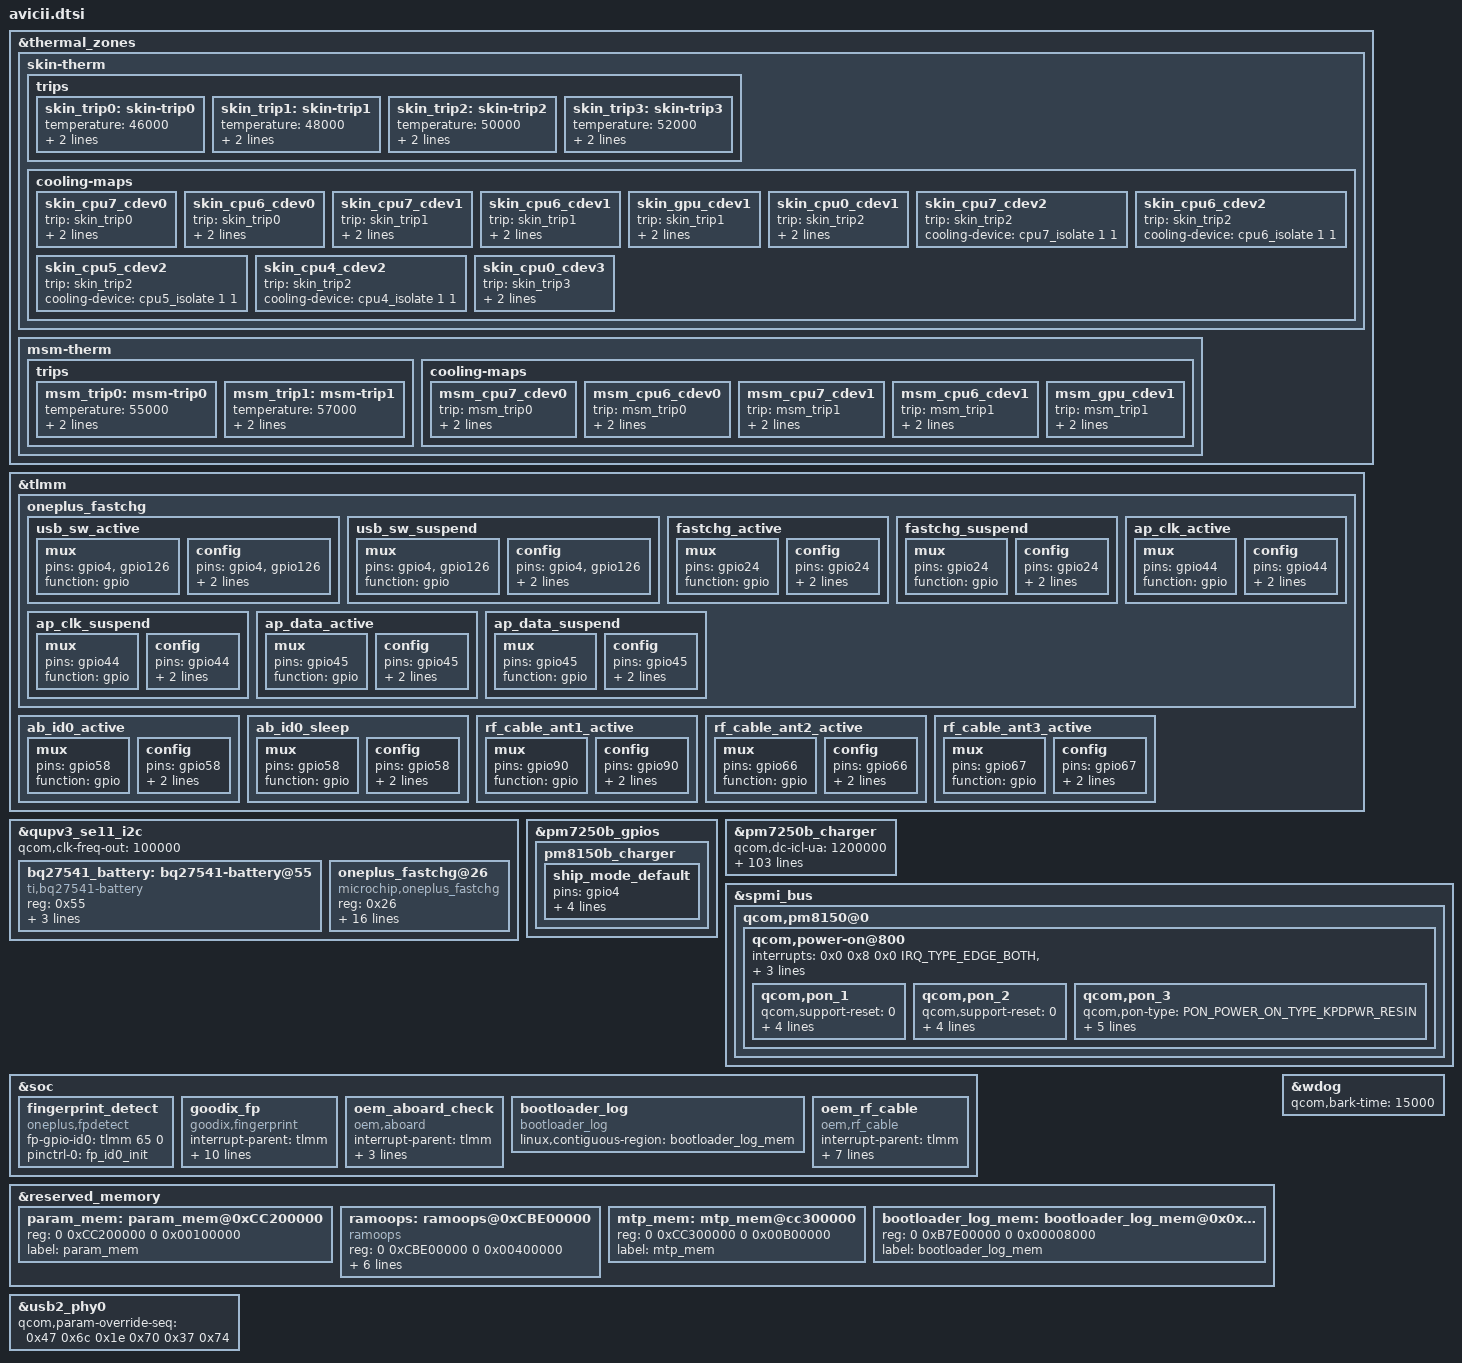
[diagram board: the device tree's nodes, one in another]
/*this is for different project dtsi*/
&thermal_zones {
	skin-therm {
		trips {
			skin_trip0: skin-trip0 {
				temperature = <46000>;
				hysteresis = <2000>;
				type = "passive";
			};

			skin_trip1: skin-trip1 {
				temperature = <48000>;
				hysteresis = <2000>;
				type = "passive";
			};

			skin_trip2: skin-trip2 {
				temperature = <50000>;
				hysteresis = <2000>;
				type = "passive";
			};

			skin_trip3: skin-trip3 {
				temperature = <52000>;
				hysteresis = <2000>;
				type = "passive";
			};
		};

		cooling-maps {
			skin_cpu7_cdev0 {
				trip = <&skin_trip0>;
					/* throttle from fmax to 1766400KHz */
				cooling-device =
					<&CPU7 (THERMAL_MAX_LIMIT-3)
						(THERMAL_MAX_LIMIT-3)>;
			};

			skin_cpu6_cdev0 {
				trip = <&skin_trip0>;
					/* throttle from fmax to 1728000KHz */
				cooling-device =
					<&CPU6 (THERMAL_MAX_LIMIT-4)
						(THERMAL_MAX_LIMIT-4)>;
			};

			skin_cpu7_cdev1 {
				trip = <&skin_trip1>;
					/* throttle from fmax to 1401600KHz */
				cooling-device = <&CPU7 (THERMAL_MAX_LIMIT-2)
						(THERMAL_MAX_LIMIT-2)>;
			};

			skin_cpu6_cdev1 {
				trip = <&skin_trip1>;
					/* throttle from fmax to 1478400KHz */
				cooling-device =
					<&CPU6 (THERMAL_MAX_LIMIT-3)
						(THERMAL_MAX_LIMIT-3)>;
			};

			skin_gpu_cdev1 {
				trip = <&skin_trip1>;
				cooling-device = <&msm_gpu (THERMAL_MAX_LIMIT-2)
						(THERMAL_MAX_LIMIT-2)>;
			};

			skin_cpu0_cdev1 {
				trip = <&skin_trip2>;
					/* throttle from fmax to 864000KHz */
				cooling-device =
					<&CPU0 (THERMAL_MAX_LIMIT-3)
						(THERMAL_MAX_LIMIT-3)>;
			};

			skin_cpu7_cdev2 {
				trip = <&skin_trip2>;
					/* throttle to close cpu7 */
				cooling-device = <&cpu7_isolate 1 1>;
			};

			skin_cpu6_cdev2 {
				trip = <&skin_trip2>;
					/* throttle to close cpu6 */
				cooling-device = <&cpu6_isolate 1 1>;
			};

			skin_cpu5_cdev2 {
				trip = <&skin_trip2>;
					/* throttle to close cpu5 */
				cooling-device = <&cpu5_isolate 1 1>;
			};

			skin_cpu4_cdev2 {
				trip = <&skin_trip2>;
					/* throttle to close cpu4 */
				cooling-device = <&cpu4_isolate 1 1>;
			};

			skin_cpu0_cdev3 {
				trip = <&skin_trip3>;
					/* throttle from fmax to 614400KHz */
				cooling-device =
					<&CPU0 (THERMAL_MAX_LIMIT-2)
						(THERMAL_MAX_LIMIT-2)>;
			};
		};
	};

	msm-therm {
		trips {
			msm_trip0: msm-trip0 {
				temperature = <55000>;
				hysteresis = <2000>;
				type = "passive";
			};

			msm_trip1: msm-trip1 {
				temperature = <57000>;
				hysteresis = <2000>;
				type = "passive";
			};
		};

		cooling-maps {
			msm_cpu7_cdev0 {
				trip = <&msm_trip0>;
					/* throttle from fmax to 2304000KHz */
				cooling-device =
					<&CPU7 (THERMAL_MAX_LIMIT-6)
						(THERMAL_MAX_LIMIT-6)>;
			};

			msm_cpu6_cdev0 {
				trip = <&msm_trip0>;
					/* throttle from fmax to 1900800KHz */
				cooling-device =
					<&CPU6 (THERMAL_MAX_LIMIT-5)
						(THERMAL_MAX_LIMIT-5)>;
			};

			msm_cpu7_cdev1 {
				trip = <&msm_trip1>;
					/* throttle from fmax to 1996800KHz */
				cooling-device = <&CPU0 (THERMAL_MAX_LIMIT-4)
						(THERMAL_MAX_LIMIT-4)>;
			};

			msm_cpu6_cdev1 {
				trip = <&msm_trip1>;
					/* throttle from fmax to 1728000KHz */
				cooling-device = <&CPU0 (THERMAL_MAX_LIMIT-4)
						(THERMAL_MAX_LIMIT-4)>;
			};

			msm_gpu_cdev1 {
				trip = <&msm_trip1>;
				cooling-device = <&msm_gpu (THERMAL_MAX_LIMIT-1)
						(THERMAL_MAX_LIMIT-1)>;
			};
		};
	};
};

&tlmm {
	oneplus_fastchg {
		usb_sw_active: usb_sw_active {
			mux {
				pins = "gpio4", "gpio126";
				function = "gpio";
			};

			config {
				pins = "gpio4", "gpio126";
				drive-strength = <16>;
				bias-pull-down;
			};
		};

		usb_sw_suspend: usb_sw_suspend {
			mux {
				pins = "gpio4", "gpio126";
				function = "gpio";
			};

			config {
				pins = "gpio4", "gpio126";
				drive-strength = <2>;
				bias-disable;
			};
		};

		fastchg_active: fastchg_active {
			mux {
				pins = "gpio24";
				function = "gpio";
			};

			config {
				pins = "gpio24";
				drive-strength = <16>;
				bias-pull-up;
			};
		};

		fastchg_suspend: fastchg_suspend {
			mux {
				pins = "gpio24";
				function = "gpio";
			};

			config {
				pins = "gpio24";
				drive-strength = <2>;
				bias-disable;
			};
		};

		ap_clk_active: ap_clk_active {
			mux {
				pins = "gpio44";
				function = "gpio";
			};

			config {
				pins = "gpio44";
				drive-strength = <16>;
				bias-pull-up;
			};
		};

		ap_clk_suspend: ap_clk_suspend {
			mux {
				pins = "gpio44";
				function = "gpio";
			};

			config {
				pins = "gpio44";
				drive-strength = <2>;
				bias-disable;
			};
		};

		ap_data_active: ap_data_active {
			mux {
				pins = "gpio45";
				function = "gpio";
			};

			config {
				pins = "gpio45";
				drive-strength = <16>;
				bias-pull-up;
			};
		};

		ap_data_suspend: ap_data_suspend {
			mux {
				pins = "gpio45";
				function = "gpio";
			};

			config {
				pins = "gpio45";
				drive-strength = <2>;
				bias-disable;
			};
		};
	};

	ab_id0_active: ab_id0_active {
		mux {
			pins = "gpio58";
			function = "gpio";
		};
		config {
			pins = "gpio58";
			drive-strength = <2>;
			bias-pull-up;
		};
	};
	ab_id0_sleep: ab_id0_sleep {
		mux {
			pins = "gpio58";
			function = "gpio";
		};
		config {
			pins = "gpio58";
			drive-strength = <2>;
			bias-disable;
		};
	};
        rf_cable_ant1_active: rf_cable_ant1_active {
            mux {
                pins = "gpio90";
                function = "gpio";
            };
            config {
                pins = "gpio90";
                drive-strength = <2>;
                bias-pull-up;
            };
        };
        rf_cable_ant2_active: rf_cable_ant2_active {
            mux {
                pins = "gpio66";
                function = "gpio";
            };
            config {
                pins = "gpio66";
                drive-strength = <2>;
                bias-pull-up;
            };
        };
        rf_cable_ant3_active: rf_cable_ant3_active {
            mux {
                pins = "gpio67";
                function = "gpio";
            };
            config {
                pins = "gpio67";
                drive-strength = <2>;
                bias-pull-up;
            };
        };
};
/* @bsp, 2019/07/08 Battery & Charging porting END */

&qupv3_se11_i2c {
	status = "ok";
	qcom,clk-freq-out = <100000>;
	bq27541_battery:bq27541-battery@55 {
		status = "ok";
		compatible = "ti,bq27541-battery";
		reg = <0x55>;
		qcom,modify-soc-smooth;
		qcom,battery-full-param;//only for wite battery full param in guage dirver probe on 7250 platform 
		op,bat-4p45v;
	};

	oneplus_fastchg@26{
		status = "ok";
		compatible = "microchip,oneplus_fastchg";
		reg = <0x26>;
		microchip,mcu-en-gpio = <&tlmm 24 0x00>;
		microchip,usb-sw-1-gpio = <&tlmm 4 0x00>;
		microchip,usb-sw-2-gpio = <&tlmm 126 0x00>;
		microchip,ap-clk = <&tlmm 44 0x00>;
		microchip,ap-data = <&tlmm 45 0x00>;

		pinctrl-names = "mux_fastchg_active",
		"mux_fastchg_suspend",
		"mcu_data_active",
		"mcu_data_suspend";
		pinctrl-0 = <&fastchg_active
		&usb_sw_active
		&ap_clk_active>;
		pinctrl-1 = <&usb_sw_suspend
		&fastchg_suspend
		&ap_clk_suspend>;
		pinctrl-2 =<&ap_data_active>;
		pinctrl-3 =<&ap_data_suspend>;
		op,fw-erase-count = <384>;
		op,fw-addr-low = <0x88>;
		op,fw-addr-high = <0>;
		op,4300mAh_4p45_support;
		op,mcl_verion;
	};
};

&pm7250b_gpios {
	pm8150b_charger {
		ship_mode_default: ship_mode_default {
			pins = "gpio4";
			function = "normal";
			power-source = <0>;
			bias-disable;
			input-disable;
		};
	};
};


&pm7250b_charger {
	qcom,dc-icl-ua = <1200000>;
	qcom,fcc-max-ua = <2000000>;
	qcom,usb-icl-ua = <1800000>;
	qcom,fv-max-uv = <4365000>;
	/* ibatmax setting for different temp regions */
	ibatmax-little-cold-ma = <350>;
	ibatmax-cool-ma = <2000>;
	ibatmax-little-cool-ma = <2000>;
	ibatmax-pre-normal-ma = <2000>;
	ibatmax-normal-ma = <2000>;
	ibatmax-warm-ma = <1150>;
	ibatmax-little-cool-thr-ma = <1900>;
	ibatmax-cool-thr-ma = <1150>;
	/* vbatmax setting for different temp regions */
	vbatmax-little-cold-mv = <3975>;
	vbatmax-cool-mv = <4435>;
	vbatmax-little-cool-mv = <4435>;
	vbatmax-pre-normal-mv = <4435>;
	vbatmax-normal-mv = <4435>;
	vbatmax-warm-mv = <4130>;
	little-cool-vbat-thr-mv = <4180>;
	cool-vbat-thr-mv = <4180>;
	/* vbatdet setting for different temp regions */
	vbatdet-little-cold-mv = <3675>;
	vbatdet-cool-mv = <4235>;
	vbatdet-little-cool-mv = <4335>;
	vbatdet-pre-normal-mv = <4335>;
	vbatdet-normal-mv = <4335>;
	vbatdet-warm-mv = <4030>;
	/* temp region settings */
	cold-bat-decidegc = <20>;
	little-cold-bat-decidegc = <0>;
	cool-bat-decidegc = <50>;
	little-cool-bat-decidegc = <120>;
	pre-normal-bat-decidegc = <160>;
	warm-bat-decidegc = <450>;
	hot-bat-decidegc = <500>;
	qcom,otg-cl-ua = <1500000>;
	op,sw-iterm-ma = <310>;
	op,sw-check-full-enable;
	/*ffc temp region*/
	ffc-pre-normal-decidegc = <120>;
	ffc-normal-decidegc = <350>;
	ffc-warm-decidegc = <400>;
	ffc-normal-fcc-ma = <1050>;
	ffc-warm-fcc-ma = <1100>;
	ffc-normal-cutoff-ma = <950>;
	ffc-warm-cutoff-ma = <1000>;
	ffc-full-vbat-mv = <4480>;

	/* skin thermal temp adjust the dash current */
	op,skin-thermal-high-threshold-disp-off = <42>;
	op,skin-thermal-pre-high-threshold-disp-off = <38>;
	op,skin-thermal-medium-threshold-disp-off = <39>;
	op,skin-thermal-normal-threshold-disp-off = <37>;

	op,skin-thermal-high-threshold-disp-on = <40>;
	op,skin-thermal-pre-high-threshold-disp-on = <39>;
	op,skin-thermal-little-high-threshold-disp-on = <38>;
	op,skin-thermal-pre-little-high-threshold-disp-on = <37>;
	op,skin-thermal-medium-threshold-disp-on = <36>;
	op,skin-thermal-normal-threshold-disp-on = <35>;
	op,enable-dash-current-dynamic-adjust;

	/* skin thermal temp adjust the pd current */
	op,pd-skin-thermal-high-threshold = <40>;
	op,pd-skin-thermal-normal-threshold = <38>;
	op,pd-skin-thermal-medium-threshold = <39>;
	op,pd-skin-thermal-pre-high-threshold = <39>;
	op,enable-pd-current-dynamic-adjust;

	/delete-property/ qcom,sw-jeita-enable;

	/*otg low battery current limit*/
	op,otg-icl-ctrl-enable;
	otg-low-battery-thr = <15>;
	otg-low-bat-icl-thr = <1000000>;
	otg-normal-bat-icl-thr = <1500000>;

	/* for usb connecter temperature check */
	op,normal-check-interval-period = <300>;
	op,fast-check-interval-period = <50>;
	op,fast-check-threshold-temp = <33>;
	op,high-temp-short-check-timeout = <1500>;
	op,first-protect-connecter-temp = <60>;
	op,second-protect-connecter-temp = <45>;
	op,second-protect-interval-temp = <14>;
	op,third-protect-rise-rate = <3>;
	op,third-protect-loop-temp = <40>;
	op,third-protect-interval-temp = <8>;
	op,third-protect-base-temp = <20>;

	/* for charge current&voltage curve optimize */
	op,fv-offset-voltage-mv = <50>;

	/* for 4p45v not charge full issue add sw full count numb */
	op,full-count-sw-numb = <2>;

	/* other settings */
	/*disable lpd*/
	qcom,lpd-disable;
	qcom,cutoff-voltage-with-charger = <3250>;
	qcom,msm-bus,name = "dash_clk_vote";
	qcom,msm-bus,num-cases = <2>;
	qcom,msm-bus,num-paths = <1>;
	qcom,msm-bus,vectors-KBps = <1 731 0 300000000>,
					<1 731 0 0>;

	/*usb connector hw auto detection*/
	op,usb-check = <&tlmm 68 0x00>;

	/* for external ship mode suppot */
	op,stm-ctrl-gpio = <&pm7250b_gpios 4 0x00>;
	pinctrl-names = "op_ship_mode_default",
			"op_usb_temp_adc_default",
			"op_usb_temp_adc_sec";

	pinctrl-0 = <&ship_mode_default>;
	pinctrl-1 = <&usb_tem1_adc_gpio_default>;
	pinctrl-2 = <&usb_tem2_adc_gpio_default>;

	io-channels = <&pm7250b_vadc ADC_USB_IN_V_16>,
		      <&pm7250b_vadc ADC_USB_IN_I>,
		      <&pm7250b_vadc ADC_CHG_TEMP>,
		      <&pm7250b_vadc ADC_DIE_TEMP>,
		      <&pm7250b_vadc ADC_AMUX_THM3_PU2>,
		      <&pm7250b_vadc ADC_SBUx>,
		      <&pm7250b_vadc ADC_VPH_PWR>,
		      <&pm7250b_vadc ADC_AMUX_THM1_PU2>,
		      <&pm8150l_vadc ADC_GPIO3_PU2>,
		      <&pm8150_vadc ADC_GPIO1_PU1>,
		      <&pm8150l_vadc ADC_GPIO2_PU1>;

	io-channel-names = "usb_in_voltage",
			   "usb_in_current",
			   "chg_temp",
			   "die_temp",
			   "conn_temp",
			   "sbux_res",
			   "vph_voltage",
			   "skin_temp",
			   "skin_therm",
			   "usb_tem1_adc",
			   "usb_tem2_adc";

	/* VBUS control config */
	op,vbus-ctrl-gpio = <&pm7250b_gpios 7 GPIO_ACTIVE_LOW>;
};


&spmi_bus {
	qcom,pm8150@0 {
		qcom,power-on@800 {
			interrupts = <0x0 0x8 0x0 IRQ_TYPE_EDGE_BOTH>,
			             <0x0 0x8 0x1 IRQ_TYPE_EDGE_BOTH>,
			             <0x0 0x8 0x5 IRQ_TYPE_EDGE_BOTH>;
			interrupt-names = "kpdpwr", "resin", "kpdpwr-resin-bark";
			qcom,s3-src = "kpdpwr-and-resin";

			qcom,pon_1 {
				qcom,support-reset = <0>;
				qcom,s1-timer = <6720>;
				qcom,s2-timer = <2000>;
				qcom,s2-type = <PON_POWER_OFF_TYPE_HARD_RESET>;
				qcom,pull-up;
			};

			qcom,pon_2 {
				qcom,support-reset = <0>;
				qcom,s1-timer = <6720>;
				qcom,s2-timer = <2000>;
				qcom,s2-type = <PON_POWER_OFF_TYPE_HARD_RESET>;
				qcom,pull-up;
			};

			qcom,pon_3 {
				qcom,pon-type = <PON_POWER_ON_TYPE_KPDPWR_RESIN>;
				qcom,support-reset = <0>;
				qcom,s1-timer = <6720>;
				qcom,s2-timer = <2000>;
				qcom,s2-type = <PON_POWER_OFF_TYPE_HARD_RESET>;
				qcom,pull-up;
			};
		};
	};
};

&soc {
	fingerprint_detect:fingerprint_detect {
		compatible = "oneplus,fpdetect";
		fp-gpio-id0 = <&tlmm 65 0>;
		pinctrl-names = "fp_id_init";
		pinctrl-0 = <&fp_id0_init >;
	};

	goodix_fp {
		compatible = "goodix,fingerprint";
		interrupt-parent = <&tlmm>;
		fp-gpio-irq = <&tlmm 112 0x00>;
		fp-gpio-reset = <&tlmm 63 0x00>;
		fp-gpio-enable = <&pm8150_gpios 7 0x00>;
		fp-gpio-1v8 = <&pm8150_gpios 6 0x00 >;
		ldo-supply = <&pm8150a_l9>; // pm660l_l5 for goodix_fp
		pinctrl-names = "fp_en_init","fp_dis_init";
		pinctrl-0 = <&fp_vdd_init &fp_1v8_init &fp_irq_init>; /*high*/
		pinctrl-1 = <&fp_vdd_dis_init &fp_1v8_dis_init>; /*low*/
		gpios = <&pm8150_gpios 7 0x00>,
			<&pm8150_gpios 6 0x00 >,
			<&tlmm 112 0x00>;
		status = "okay";
	};

 	oem_aboard_check:oem_aboard_check {
 		compatible = "oem,aboard";
 		interrupt-parent = <&tlmm>;
 		oem,aboard-gpio-0 = <&tlmm 58 0>;
 		pinctrl-names = "oem_aboard_active","oem_aboard_sleep";
 		pinctrl-0 = <&ab_id0_active>;
		pinctrl-1 = <&ab_id0_sleep>;
 	};

	bootloader_log {
		compatible = "bootloader_log";
		linux,contiguous-region = <&bootloader_log_mem>;
	};
	oem_rf_cable:oem_rf_cable {
		compatible = "oem,rf_cable";
		interrupt-parent = <&tlmm>;
		rf,cable-gpio-0 = <&tlmm 90 0>;
		rf,cable-gpio-1 = <&tlmm 66 0>;
		rf,cable-gpio-2 = <&tlmm 67 0>;
		rf,cable-support-timer = <0>;
		oem,rf_uevent_feature_enable;
		pinctrl-names = "oem_rf_cable_active";
		pinctrl-0 = <&rf_cable_ant1_active &rf_cable_ant2_active &rf_cable_ant3_active>;
	};
};

&reserved_memory {
	param_mem: param_mem@0xCC200000 {
		reg = <0 0xCC200000 0 0x00100000>;
		label = "param_mem";
	};

	ramoops: ramoops@0xCBE00000 {
		compatible = "ramoops";
		reg = <0 0xCBE00000 0 0x00400000>;
		record-size =  <0x40000>; //256x1024
		console-size = <0x40000>;
		ftrace-size =  <0x40000>;
		pmsg-size=         <0x200000>;
		devinfo-size=  <0x01000>;
		ecc-size=          <0x0>;
	};

	mtp_mem: mtp_mem@cc300000 {
		reg = <0 0xCC300000 0 0x00B00000>;
		label = "mtp_mem";
	};

	bootloader_log_mem: bootloader_log_mem@0x0xB7E00000 {
		reg = <0 0xB7E00000 0 0x00008000>;
		label = "bootloader_log_mem";
	};
};

&wdog{
	qcom,bark-time = <15000>;
};

/* @bsp, 2019/10/08 usb config START*/
&usb2_phy0 {
	qcom,param-override-seq =
		<0x47 0x6c /*Disconnection voltage +21.56%*/
		0x1e 0x70 /*Pre-emphasis:4x DC voltage level:+17.80%*/
		0x37 0x74>;
};
/* @bsp, 2019/10/08 usb config END*/
